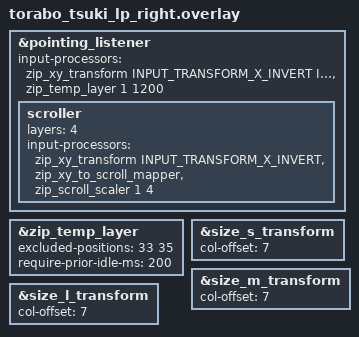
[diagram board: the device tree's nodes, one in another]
#include "torabo_tsuki_lp.dtsi"
#include <input/processors.dtsi>
#include <dt-bindings/zmk/input_transform.h>

&pointing_listener {
    /* 基本のマウス変換（X/Y 反転）と一時レイヤー（タイムアウト）を適用 */
    input-processors = <
        &zip_xy_transform INPUT_TRANSFORM_X_INVERT INPUT_TRANSFORM_Y_INVERT
        &zip_temp_layer 1 1200
    >;

    scroller {
        layers = <4>; /* 意図に合わせて確認 */
        input-processors = <
            &zip_xy_transform INPUT_TRANSFORM_X_INVERT
            &zip_xy_to_scroll_mapper
            &zip_scroll_scaler 1 4
        >;
    };
};

/* zip_temp_layer は一つにまとめる */
&zip_temp_layer {
    /* 非マウスキーを押したらタイムアウトに関係なく抜ける */
    excluded-positions = <
        33  /* J or L? 実際のキーインデックスを確認 */
        35
    >;

    /* キー入力中の誤爆防止 */
    require-prior-idle-ms = <200>;
};


/*キー入力中のオートマウスレイヤー誤爆防止*/  //auto
&zip_temp_layer {
    require-prior-idle-ms = <200>;
};

&size_s_transform {
    col-offset = <7>;
};

&size_m_transform {
    col-offset = <7>;
};

&size_l_transform {
    col-offset = <7>;
};
